# nrf5001 register map
Vendor: Nordic Semiconductor; Series: nRF50; File version: 1
CPU: CM0 r0p4, little endian, no MPU, no FPU, 2 interrupt priority bits, 32 interrupts
Registers are 32-bit, read-write, reset 0x0 unless marked. A register's access mark holds for its fields unless they carry their own. Offsets are from the block's base; [hi:lo] are bit positions; lines under a group give offsets from that group; {n}, {i} and the like mark numbered series; 'fields as' and 'values as' point back to an identical list; <NAME> marks a mode.

## RADIO (part 2 of 2) — 2.4 GHz radio
Base 0x40002000
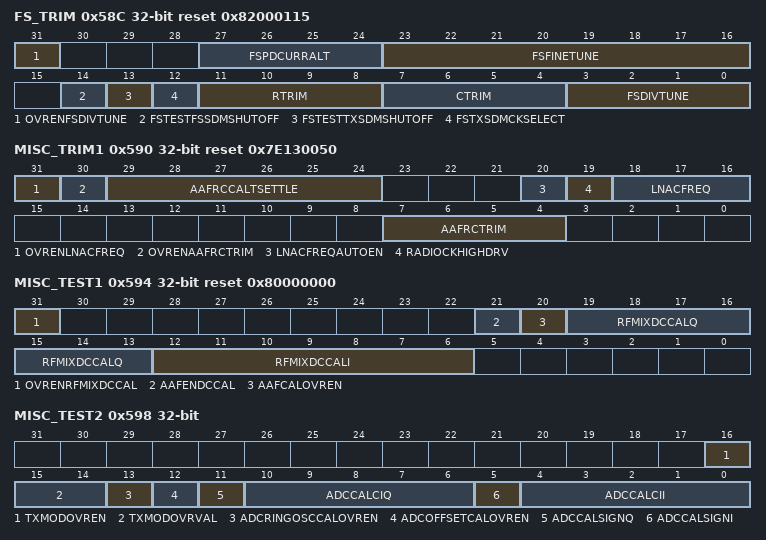
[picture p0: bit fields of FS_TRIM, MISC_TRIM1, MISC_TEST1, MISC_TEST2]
0x58C FS_TRIM reset 0x82000115 — Fs misc trim
  [31] OVRENFSDIVTUNE — if '1' enable override for FSDIVTUNE
  [27:24] FSPDCURRALT — Internal register to set FSPDCURR differently for some channels if FICR FSPDCURROPT is set to 1
  [23:16] FSFINETUNE — RF frequency adjustment (signed), LSB corresponds to 2 kHz, i.e. a range of +/-256 kHz
  [14] FSTESTFSSDMSHUTOFF — fsTestFsSdmShutoff. 1: Shutoff FsSDM, highest priority
  [13] FSTESTTXSDMSHUTOFF — fsTestTxSdmShutoff. 1: Shutoff TxSDM, e.g. for testing RX phase noise, highest priority
  [12] FSTXSDMCKSELECT — fsTxSdmCkSelect. 0: ck64MFs, 1: ck32M
  [11:8] RTRIM — Trim value for R in loop filter
  [7:4] CTRIM — Trim value for C in loop filter
  [3:0] FSDIVTUNE — Trim value for DIV2_4
0x590 MISC_TRIM1 reset 0x7E130050 — Misc Aaf/ADC trim related
  [31] OVRENLNACFREQ — if '1' enable override for LNACFREQ
  [30] OVRENAAFRCTRIM — if '1' enable override for AAFRCTRIM
  [29:24] AAFRCCALTSETTLE — Deprecated field - Sets number of clock pulses in the SETTLE state (calEngineTsettle)
  [20] LNACFREQAUTOEN — LNACFREQ automatically set based on selected channel
  [19] RADIOCKHIGHDRV — Enable high drive on RADIO_CK module
  [18:16] LNACFREQ — Change centre frequency of LNA LC tank
  [7:4] AAFRCTRIM — Process compensation for R and C
0x594 MISC_TEST1 reset 0x80000000 — Misc Aaf/ADC trim related
  [31] OVRENRFMIXDCCAL — if '1' enable override for RFMIXDCCALI/Q. RfMix calibration must only be run after the radio is fully powered up.
  [21] AAFENDCCAL — Enable DCCAL
  [20] AAFCALOVREN — 0: override with values in PAR1 1: use values from CalibrationEngineCore
  [19:13] RFMIXDCCALQ — AAF/RFMIX dc calibration of Q channel
  [12:6] RFMIXDCCALI — AAF/RFMIX dc calibration of I channel
0x598 MISC_TEST2 — Misc Aaf/ADC trim related
  [16] TXMODOVREN
  [15:14] TXMODOVRVAL
  [13] ADCRINGOSCCALOVREN — 1: override with values in SPI 0: use values from CalibrationEngineCore
  [12] ADCOFFSETCALOVREN — 1: override with values in SPI 0: use values from CalibrationEngineCore
  [11] ADCCALSIGNQ — ADC cal sign for Q
  [10:6] ADCCALCIQ — ADC calibration current in 'Q' comparator.
  [5] ADCCALSIGNI — ADC cal sign for I
  [4:0] ADCCALCII — ADC calibration current in 'I' comparator.
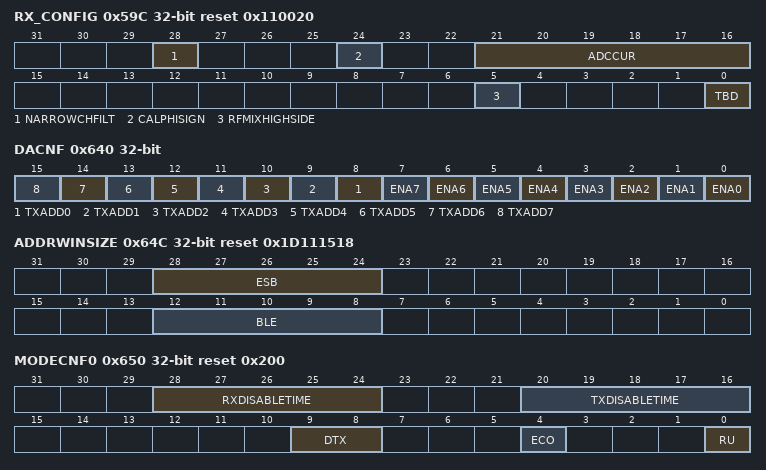
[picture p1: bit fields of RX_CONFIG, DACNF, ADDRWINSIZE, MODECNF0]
0x59C RX_CONFIG reset 0x110020 — Misc RX config
  [28] NARROWCHFILT — if '1', the channel filter is slightly narrowed
  [24] CALPHISIGN — If '1', then the sign of the phase correction value in RxIQMix is inverted
  [21:16] ADCCUR
  [5] RFMIXHIGHSIDE — Swap MIX_In and MIX_IP outputs if high (enables use of 'high side' mixing)
  [0] TBD — Deprecated field - Set to '1' if high-side LO
{0x600+4i} DAB[{i}] (i=0..7) — Description collection: Device address base segment n
  [31:0] DAB — Device address base segment n
{0x620+4i} DAP[{i}] (i=0..7) — Description collection: Device address prefix n
  [15:0] DAP — Device address prefix n
0x640 DACNF — Device address match configuration
  [n+8] TXADD{n} (n=0..7) — TxAdd for device address {n}
  [n] ENA{n} (n=0..7) — Enable or disable device address matching using device address {n}
    0=Disabled; 1=Enabled
0x64C ADDRWINSIZE reset 0x1D111518 — address match safe window size (the number of bits after detect is asserted, before starting to look for address match). Only valid when OVERRIDE22.DISABLEADDRWINDOW is '0'
  [28:24] ESB — Number of bits after detect to start search address/SFD in ESB mode
  [12:8] BLE — Number of bits after detect to start search address/SFD in BLE mode
0x650 MODECNF0 reset 0x200 — Radio mode configuration register 0
  [28:24] RXDISABLETIME — Transition time from RXDISABLE state to DISABLED state
  [20:16] TXDISABLETIME — Transition time from TXDISABLE state to DISABLED state
  [9:8] DTX — Default TX value
    0=B1 (Transmit '1'); 1=B0 (Transmit '0'); 2=Center (Transmit center frequency)
  [4] ECO — Energy mode
    0=Default energy mode; 1=Eco (Eco (energy) mode)
  [0] RU — Radio ramp-up time
    0=Default ramp-up time (tRXEN and tTXEN), compatible with firmware written for nRF51; 1=Fast ramp-up (tRXEN,FAST and tTXEN,FAST), see electrical specification for more information
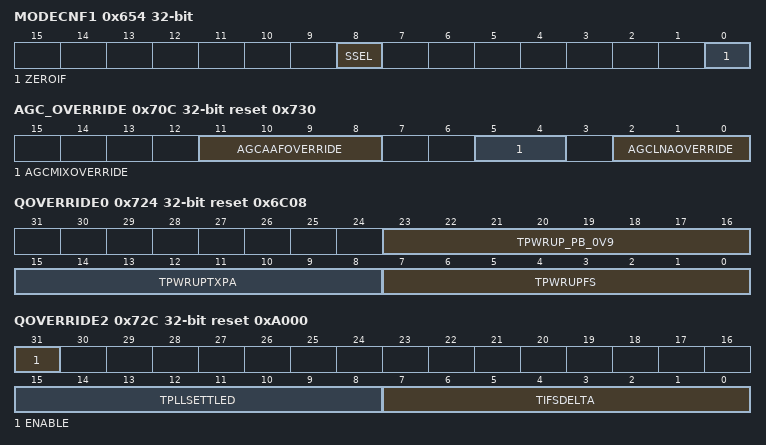
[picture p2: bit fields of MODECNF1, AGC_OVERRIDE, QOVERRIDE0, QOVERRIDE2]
0x654 MODECNF1 — Radio mode configuration register 1
  [8] SSEL — Sideband select
    0=Low (Low-side LO); 1=High-side LO
  [0] ZEROIF
    0=Default mode (heterodyne); 1=Zero-IF mode
0x704 AGC_TOGGLE — Constant AGC Gain switching, Debug
  [1:0] AGC_TOGGLE — Enable or disable functional testmode for AGC
    0=Disabled; 1=Enabled
0x708 AGC_EN reset 0x1 — AGC enable
  [0] AGC_EN — Enable or disable AGC
    0=Disabled; 1=Enabled
0x70C AGC_OVERRIDE reset 0x730 — Gain setting
  [11:8] AGCAAFOVERRIDE — Override for Aaf gain
  [5:4] AGCMIXOVERRIDE — Override for Mix gain
  [2:0] AGCLNAOVERRIDE — Override for Lna gain
0x724 QOVERRIDE0 reset 0x6C08 — Trim value override register 0 for nRF52
  [23:16] TPWRUP_PB_0V9 — Override for tPWRUP_PB_0V9
  [15:8] TPWRUPTXPA — Override for tPwrupTxPa
  [7:0] TPWRUPFS — Override for tPwrupFs
0x728 QOVERRIDE1 reset 0x680000 — Trim value override register 1 for nRF52
  [23:16] TPWRUPTX — Override for tPwrupTx
0x72C QOVERRIDE2 reset 0xA000 — Trim value override register 2 for nRF52
  [31] ENABLE — if '1' enable override for TIFSDELTA
  [15:8] TPLLSETTLED — Override for tPllSettled
  [7:0] TIFSDELTA — Override for tIfsDelta
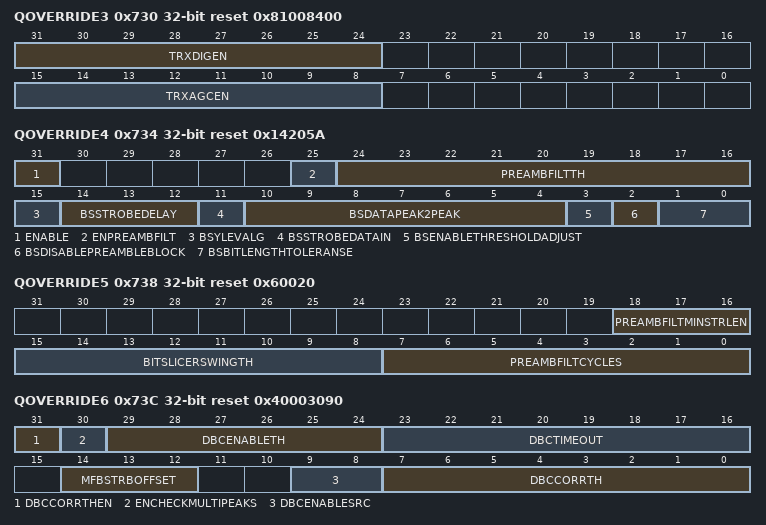
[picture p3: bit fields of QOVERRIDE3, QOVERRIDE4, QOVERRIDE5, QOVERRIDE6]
0x730 QOVERRIDE3 reset 0x81008400 — Trim value override register 3 for nRF52
  [31:24] TRXDIGEN — Override for tRxDigEn
  [15:8] TRXAGCEN — Override for tRxAgcEn
0x734 QOVERRIDE4 reset 0x14205A — Trim value override register 4 for nRF52
  [31] ENABLE — Enable or disable override of default trim values
    0=Disabled; 1=Enabled
  [25] ENPREAMBFILT — Enable preamble filter
  [24:16] PREAMBFILTTH — Threshold for the preamble filter
  [15] BSYLEVALG — Override for bsYlevAlg
  [14:12] BSSTROBEDELAY — Override for bsStrobeDelay
  [11] BSSTROBEDATAIN — Override for bsStrobeDataIn
  [10:4] BSDATAPEAK2PEAK — Override for bsDataPeak2Peak
  [3] BSENABLETHRESHOLDADJUST — Override for bsEnableThresholdAdjust
  [2] BSDISABLEPREAMBLEBLOCK — Override for bsDisablePreambleBlock
  [1:0] BSBITLENGTHTOLERANSE — Override for bsBitLengthToleranse
0x738 QOVERRIDE5 reset 0x60020 — Trim value override register 5 for nRF52
  [18:16] PREAMBFILTMINSTRLEN — Override value for preambFiltMinStrLen
  [15:8] BITSLICERSWINGTH — Override value for bitSlicerSwingTh
  [7:0] PREAMBFILTCYCLES — Override value for preambFiltCycles
0x73C QOVERRIDE6 reset 0x40003090 — Trim value override register 6 for nRF52
  [31] DBCCORRTHEN — Override value enable for DBCCORRTH and MFBSTRBOFFSET
  [30] ENCHECKMULTIPEAKS — Enable checking of several correlator peaks in hypermode
  [29:24] DBCENABLETH — Override value for correlator enable threshold
  [23:16] DBCTIMEOUT — Override value for correlator timeout,in bit periods (hypermode)
  [14:12] MFBSTRBOFFSET — Override value for strobe offset
  [9:8] DBCENABLESRC — Override value for dbcEnableSrc
    0=Always on when not address match; 1=BBLogMag (When bbLogMag is above a threshold); 2=BitSlicerSwing (When a certain time has gone since the input to the bitslicer was above BITSLICERSWINGTH); 3=Both BBLogMag and BitSlicerSwing
  [7:0] DBCCORRTH — Override value for correlation Threshold
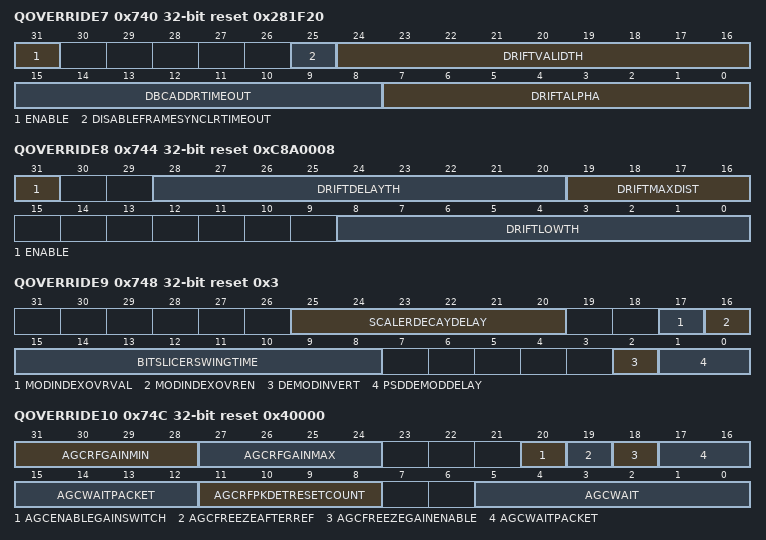
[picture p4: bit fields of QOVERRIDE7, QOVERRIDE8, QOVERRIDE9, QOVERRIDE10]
0x740 QOVERRIDE7 reset 0x281F20 — Trim value override register 7 for nRF52
  [31] ENABLE — Override enable for DRIFTALPHA, DBCADDRTIMEOUT and DRIFTVALIDTH
  [25] DISABLEFRAMESYNCLRTIMEOUT — Disable framesync timeout (early address match timeout) for BLE LR mode. No override-enable to set for this (hypermode)
  [24:16] DRIFTVALIDTH — Override value for driftValidTh, drift estimator (hypermode)
  [15:8] DBCADDRTIMEOUT — Override value for address match timeout, [in bit periods] (hypermode)
  [7:0] DRIFTALPHA — Override value for IIR feedback , drift estimator (hypermode)
0x744 QOVERRIDE8 reset 0xC8A0008 — Trim value override register 8 for nRF52
  [31] ENABLE — Override value enable for override register 8
  [28:20] DRIFTDELAYTH — Override value for driftDelayTh, drift estimator (hypermode)
  [19:16] DRIFTMAXDIST — Override value for driftMaxDist, drift estimator (hypermode)
  [8:0] DRIFTLOWTH — Override value for driftLowTh, drift estimator (hypermode)
0x748 QOVERRIDE9 reset 0x3 — Trim value override register 9 for nRF52
  [25:20] SCALERDECAYDELAY — Decay delay for the IQ scaler
  [17] MODINDEXOVRVAL
  [16] MODINDEXOVREN
  [15:8] BITSLICERSWINGTIME
  [2] DEMODINVERT — Override value for demodInvert (standard and hyper)
  [1:0] PSDDEMODDELAY — Override value for psdDemodDelay (standard mode)
0x74C QOVERRIDE10 reset 0x40000 — Trim value override register 10 for nRF52
  [31:28] AGCRFGAINMIN — Override value for agcRFGainMin
  [27:24] AGCRFGAINMAX — Override value for agcRFGainMax
  [20] AGCENABLEGAINSWITCH — Override value for agcEnableGainSwitch
  [19] AGCFREEZEAFTERREF — Modifier bit for AGCFREEZEGAINENABLE
    0=EntireCTE (Gain freeze will apply to whole CTE); 1=AfterRefPeriod (Gain freeze will apply only after the reference period of the CTE)
  [18] AGCFREEZEGAINENABLE — Override AGC gain setting during CTE
    0=Adjust (AGC gain settings will keep adjusting during CTE); 1=Freeze (AGC gain settings will freeze (not keep adjusting) during CTE)
  [17:12] AGCWAITPACKET — Override value for agcWaitPacket
  [11:8] AGCRFPKDETRESETCOUNT — Override value for agcRFpkDetResetCount
  [5:0] AGCWAIT — Override value for agcWait
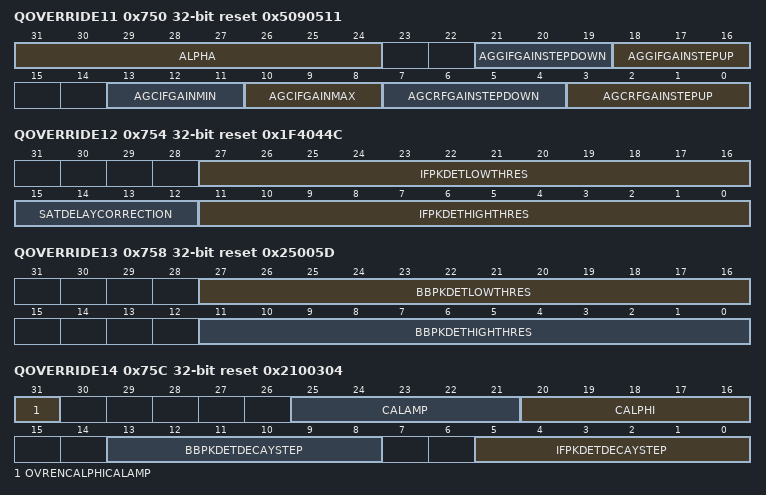
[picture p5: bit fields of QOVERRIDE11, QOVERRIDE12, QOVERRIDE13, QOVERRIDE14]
0x750 QOVERRIDE11 reset 0x5090511 — Trim value override register 11 for nRF52
  [31:24] ALPHA — used in Rssi moving exponential averager
  [21:19] AGGIFGAINSTEPDOWN — Override value for aggIFgainStepDown
  [18:16] AGGIFGAINSTEPUP — Override value for aggIFgainStepUp
  [13:11] AGCIFGAINMIN — Override value for agcIFgainMin
  [10:8] AGCIFGAINMAX — Override value for agcIFgainMax
  [7:4] AGCRFGAINSTEPDOWN — Override value for agcRFgainStepDown
  [3:0] AGCRFGAINSTEPUP — Override value for agcRFgainStepUp
0x754 QOVERRIDE12 reset 0x1F4044C — Trim value override register 12 for nRF52
  [27:16] IFPKDETLOWTHRES — Override value for IfpkDetLowThres
  [15:12] SATDELAYCORRECTION — Signed correction value for how much the saturation information is delayed from the input ADC samples to the samples being stored to RAM in direction finding operation
  [11:0] IFPKDETHIGHTHRES — Override value for IfpkDetHighThres
0x758 QOVERRIDE13 reset 0x25005D — Trim value override register 13 for nRF52
  [27:16] BBPKDETLOWTHRES — Override value for BbpkDetLowThres
  [11:0] BBPKDETHIGHTHRES — Override value for BbpkDetHighThres
0x75C QOVERRIDE14 reset 0x2100304 — Trim value override register 14 for nRF52
  [31] OVRENCALPHICALAMP — if '1' enable override for CALPHI/CALAMP
  [25:21] CALAMP — Override value for calamp (programmable IandQ gain mismatch correction)
  [20:16] CALPHI — Override value for calphi (programmable IandQ phase mismatch correction)
  [13:8] BBPKDETDECAYSTEP — Override value for BbpkDetDecayStep
  [5:0] IFPKDETDECAYSTEP — Override value for IfpkDetDecayStep
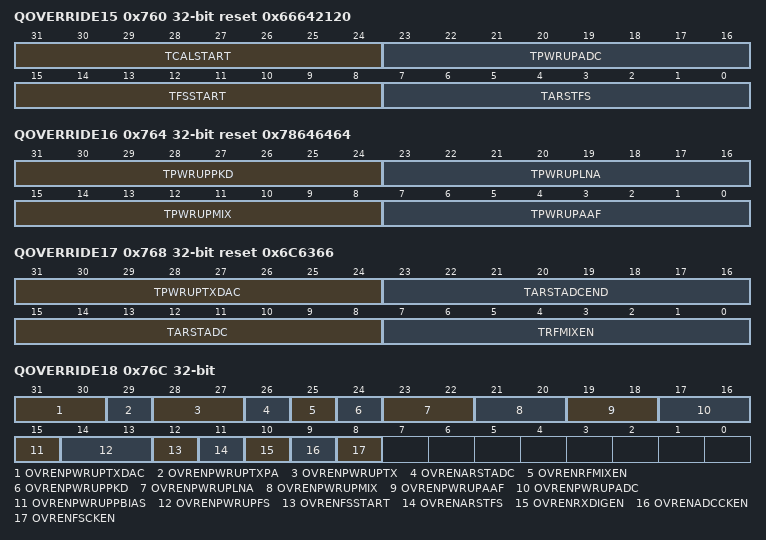
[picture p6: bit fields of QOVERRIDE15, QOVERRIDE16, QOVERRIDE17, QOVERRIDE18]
0x760 QOVERRIDE15 reset 0x66642120 — Trim value override register 15 for nRF52
  [31:24] TCALSTART — Override value for tCalStart
  [23:16] TPWRUPADC — Override value for tPwrupAdc
  [15:8] TFSSTART — Override value for tFsStart
  [7:0] TARSTFS — Override value for tArstFs
0x764 QOVERRIDE16 reset 0x78646464 — Trim value override register 16 for nRF52
  [31:24] TPWRUPPKD — Override value for tPwrupPkd
  [23:16] TPWRUPLNA — Override value for tPwrupLna
  [15:8] TPWRUPMIX — Override value for tPwrupMix
  [7:0] TPWRUPAAF — Override value for tPwrupAaf
0x768 QOVERRIDE17 reset 0x6C6366 — Trim value override register 17 for nRF52
  [31:24] TPWRUPTXDAC — Override value for tPwrupTxDac
  [23:16] TARSTADCEND — Override value for tArstAdcEnd
  [15:8] TARSTADC — Override value for tArstAdc
  [7:0] TRFMIXEN — Override value for tRfMixEn
0x76C QOVERRIDE18 — Trim value override register 18 for nRF52
  [31:30] OVRENPWRUPTXDAC — Override enable: ovrEnPwrupTxDac
  [29] OVRENPWRUPTXPA — Override enable: ovrEnPwrupTxPa
  [28:27] OVRENPWRUPTX — Override enable: ovrEnPwrupTx
  [26] OVRENARSTADC — Override enable: ovrEnArstAdc
  [25] OVRENRFMIXEN — Override enable: ovrEnRfMixEn
  [24] OVRENPWRUPPKD — Override enable: ovrEnPwrupPkd
  [23:22] OVRENPWRUPLNA — Override enable: ovrEnPwrupLna
  [21:20] OVRENPWRUPMIX — Override enable: ovrEnPwrupMix
  [19:18] OVRENPWRUPAAF — Override enable: ovrEnPwrupAaf
  [17:16] OVRENPWRUPADC — Override enable: ovrEnPwrupAdc
  [15] OVRENPWRUPPBIAS — Override enable: ovrEnPwrupPbias
  [14:13] OVRENPWRUPFS — Override enable: ovrEnPwrupFs
  [12] OVRENFSSTART — Override enable: ovrEnFsStart
  [11] OVRENARSTFS — Override enable: ovrEnArstFs
  [10] OVRENRXDIGEN — Override enable: ovrEnRxDigEn
  [9] OVRENADCCKEN — Override enable: ovrEnAdcCkEn
  [8] OVRENFSCKEN — Override enable: ovrEnFsCkEn
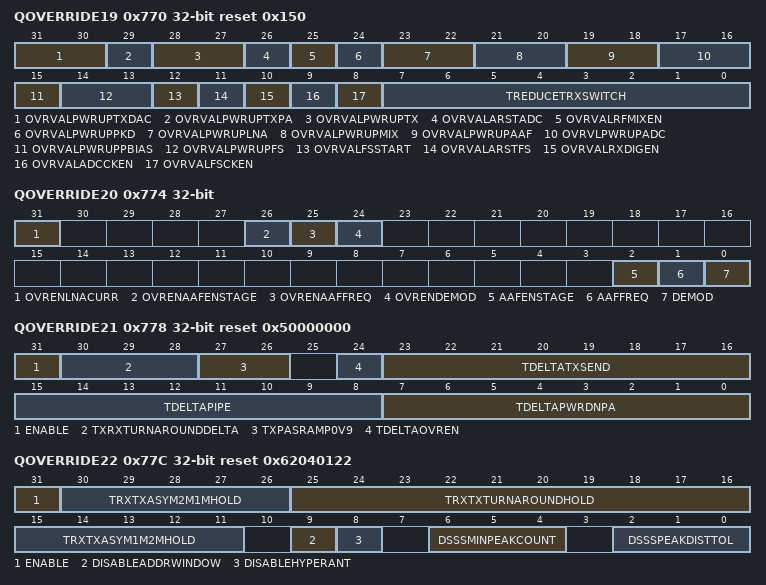
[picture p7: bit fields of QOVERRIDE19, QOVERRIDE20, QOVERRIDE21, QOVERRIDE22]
0x770 QOVERRIDE19 reset 0x150 — Trim value override register 19 for nRF52
  [31:30] OVRVALPWRUPTXDAC — Override value: ovrValPwrupTxDac
  [29] OVRVALPWRUPTXPA — Override value: ovrValPwrupTxPa
  [28:27] OVRVALPWRUPTX — Override value: ovrValPwrupTx
  [26] OVRVALARSTADC — Override value: ovrValArstAdc
  [25] OVRVALRFMIXEN — Override value: ovrValRfMixEn
  [24] OVRVALPWRUPPKD — Override value: ovrValPwrupPkd
  [23:22] OVRVALPWRUPLNA — Override value: ovrValPwrupLna
  [21:20] OVRVALPWRUPMIX — Override value: ovrValPwrupMix
  [19:18] OVRVALPWRUPAAF — Override value: ovrValPwrupAaf
  [17:16] OVRVLPWRUPADC — Override value: ovrVlPwrupAdc
  [15] OVRVALPWRUPPBIAS — Override value: ovrValPwrupPbias
  [14:13] OVRVALPWRUPFS — Override value: ovrValPwrupFs
  [12] OVRVALFSSTART — Override value: ovrValFsStart
  [11] OVRVALARSTFS — Override value: ovrValArstFs
  [10] OVRVALRXDIGEN — Override value: ovrValRxDigEn
  [9] OVRVALADCCKEN — Override value: ovrValAdcCkEn
  [8] OVRVALFSCKEN — Override value: ovrValFsCkEn
  [7:0] TREDUCETRXSWITCH — Override value: tReduceTrxSwitch
0x774 QOVERRIDE20 — Trim value override register 20 for nRF52
  [31] OVRENLNACURR — if '1' enable override for LNACURR
  [26] OVRENAAFENSTAGE — if '1' enable override for AAFENSTAGE
  [25] OVRENAAFFREQ — if '1' enable override for AAFFREQ
  [24] OVRENDEMOD — if '1' enable override for DEMOD
  [2] AAFENSTAGE — Enable extra AAF filter stage
  [1] AAFFREQ — IF frequency, 0=1MHz (for < =1Mbps), 1=2MHz (for 2Mbps)
  [0] DEMOD — Demodulator mode override value. 1=hyper,0=standard
    0=Standard (Hypermode disabled (override value)); 1=Hypermode enabled (override value)
0x778 QOVERRIDE21 reset 0x50000000 — Trim value override register 21 for nRF52
  [31] ENABLE — Enable or disable override of default trim values
    0=Disabled; 1=Enabled
  [30:28] TXRXTURNAROUNDDELTA — Tuning of radio turn around timing
  [27:26] TXPASRAMP0V9 — Debug: Control of PA RAMP time, Up/ down
  [24] TDELTAOVREN — Override enable
  [23:16] TDELTATXSEND — Override for tDeltaTxSend (full resolution)
  [15:8] TDELTAPIPE — Override for tDeltaPipe (full resolution)
  [7:0] TDELTAPWRDNPA — Override for tDeltaPwrdnPa (full resolution)
0x77C QOVERRIDE22 reset 0x62040122 — Trim value override register 22 for nRF52
  [31] ENABLE — Enable or disable override for DSSSPEAKDISTTOL and DSSSMINPEAKCOUNT
    0=Disabled; 1=Enabled
  [30:26] TRXTXASYM2M1MHOLD — TIFS positive offset when the mode is switched from 2M to 1M
  [25:16] TRXTXTURNAROUNDHOLD — Additional delay to hold Tx/Rx turnaround, full resolution [250ns]
  [15:11] TRXTXASYM1M2MHOLD — TIFS negative offset when the mode is switched from 1M to 2M
  [9] DISABLEADDRWINDOW — Disable or enable the qualification of addressMatch vs. detect
    1=Disabled; 0=Enabled
  [8] DISABLEHYPERANT — Disable or enable hypermode fix for ANT
    1=Disabled; 0=Enabled
  [6:4] DSSSMINPEAKCOUNT — Override for dsssMinPeakCount
  [2:0] DSSSPEAKDISTTOL — Override for dsssPeakDistanceTolerance
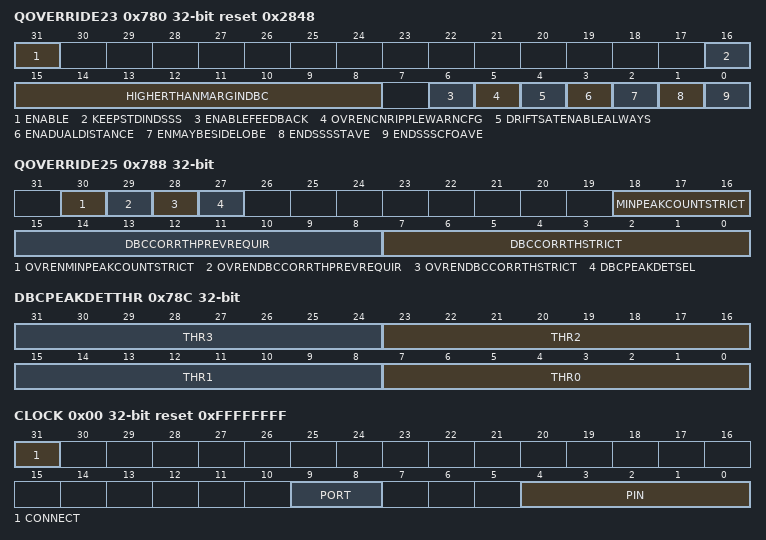
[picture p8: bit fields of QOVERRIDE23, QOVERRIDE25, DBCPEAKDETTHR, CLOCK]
0x780 QOVERRIDE23 reset 0x2848 — Trim value override register 23 for nRF52
  [31] ENABLE — Enable override for OVERRIDE23 (except HIGHERTHANMARGINDBC and OVRENCNRIPPLEWARNCFG)
  [16] KEEPSTDINDSSS — Keep standard demod in DSSS mode
  [15:8] HIGHERTHANMARGINDBC — Required peak height required for a double correlator peak to be considered higher than previous ones. The register value will be multiplied by 25 to obtain the actual margin. The bitfield is NOT subject to the enable override at bit position 31, and will always be enabled for hypermode.
  [6] ENABLEFEEDBACK — Enable decision feedback for matched filter bank
  [5] OVRENCNRIPPLEWARNCFG — Override enable for CNPEAKMINTHR and CNABSMAXTHR in the CNRIPPLEWARNCFG register
  [4] DRIFTSATENABLEALWAYS — Enable saturation in drift calculator for all modes
  [3] ENADUALDISTANCE — Allow dual distance between peaks
  [2] ENMAYBESIDELOBE — Ignore peaks from DBC which look like sidelobes
  [1] ENDSSSSTAVE — Enable strobe time averaging
  [0] ENDSSSCFOAVE — Enable CFO averaging
0x788 QOVERRIDE25 — Unspecified
  [30] OVRENMINPEAKCOUNTSTRICT — Override enable for MINPEAKCOUNTSTRICT
  [29] OVRENDBCCORRTHPREVREQUIR — Override enable for DBCCORRTHPREVREQUIR
  [28] OVRENDBCCORRTHSTRICT — Override enable for DBCCORRTHSTRICT
  [27] DBCPEAKDETSEL — DBC peak detector selection
    0=Classic (Use classic peak detector (backward compatible behavior)); 1=Differential (Use differential peak detector)
  [18:16] MINPEAKCOUNTSTRICT — Min number of peaks to detect before resyncing to another preamble while already working on a previous preamble in BleLrx.
  [15:8] DBCCORRTHPREVREQUIR — Correlation threshold for double correlator used in BleLr mode to reject a later resync using DBCCORRTHSTRICT.
  [7:0] DBCCORRTHSTRICT — Correlation threshold for double correlator used in BleLr mode to resync to another preamble while already working on a previous preamble.
0x78C DBCPEAKDETTHR — Thresholds for each peak detector instance
  [8n+7:8n] THR{n} (n=0..3) — Diff threshold {n}
0x800 DEBUGPSEL group — Unspecified
  0x00 CLOCK reset 0xFFFFFFFF — Pin select for RADIO clock (direct mode, base band debug. Refer to digip_064 and digip_061, txCk and ckDataIn signals)
    [31] CONNECT — Connection
      1=Disconnected; 0=Connected
    [9:8] PORT — Port number
    [4:0] PIN — Pin number
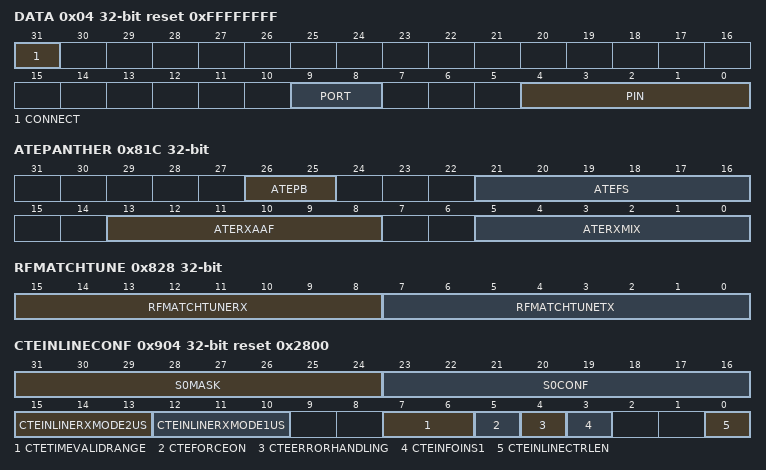
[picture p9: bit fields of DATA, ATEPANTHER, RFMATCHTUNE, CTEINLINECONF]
  0x04 DATA reset 0xFFFFFFFF — Pin select for RADIO data (direct mode, base band debug. Refer to digip_064 and digip_061, txRadioData and dataIn signals)
    fields as DEBUGPSEL.CLOCK
0x81C ATEPANTHER — Analog test bus control for Panther radio
  [26:25] ATEPB
  [21:16] ATEFS — ateFs: Configuration register for automatic test bus
  [13:8] ATERXAAF — ateRxAaf: Enable RXAAF test mode when >0
  [5:0] ATERXMIX — ateRxMix: Enable RXMix test mode when >0
0x828 RFMATCHTUNE — Adjust transformation ratio of on-chip matching Can be used for: 1) Optimise power consumption for different output power levels in TX mode 2) Optimise input impedance in RX mode.
  [15:8] RFMATCHTUNERX — Antenna match tuning for RX mode
  [7:0] RFMATCHTUNETX — Antenna match tuning for TX mode
0x900 DFEMODE — Whether to use Angle-of-Arrival (AOA) or Angle-of-Departure (AOD)
  [1:0] DFEOPMODE — Direction finding operation mode
    0=Disabled (Direction finding mode disabled); 2=AoD (Direction finding mode set to AoD); 3=AoA (Direction finding mode set to AoA)
0x904 CTEINLINECONF reset 0x2800 — Configuration for CTE inline mode
  [31:24] S0MASK — S0 bit mask to set which bit to match
  [23:16] S0CONF — S0 bit pattern to match
  [15:13] CTEINLINERXMODE2US — Spacing between samples for the samples in the SWITCHING period when CTEINLINEMODE is set
    0=8us; 1=4us; 2=2us; 3=1us; 4=500ns (0.5us); 5=250ns (0.25us); 6=125ns (0.125us)
  [12:10] CTEINLINERXMODE1US — Spacing between samples for the samples in the SWITCHING period when CTEINLINEMODE is set
    values as CTEINLINERXMODE2US
  [7:6] CTETIMEVALIDRANGE — Max range of CTETime
    0=20 in 8us unit (default) Set to 20 if parsed CTETime is larger han 20; 1=31 in 8us unit; 2=63 in 8us unit
  [5] CTEFORCEON — CTE is continuously output after CRC and only stopped by triggering TASKS_STOP. This is typically used together with the DFEEND to STOP short. AoA/AoD procedure duration is still controlled by DFECTRL1.NUMBEROF8S / CTETIME
    1=Yes (CTE is continuously transmitted after CRC until TASKS_STOP); 0=No (CTE duration is automatically determined by DFECTRL1.NUMBEROF8US / CTETIME (only correct for 1Mbps and 2Mbps modes))
  [4] CTEERRORHANDLING — Sampling/switching if CRC is not OK
    1=Yes (Sampling and antenna switching also when CRC is not OK); 0=No (No sampling and antenna switching when CRC is not OK)
  [3] CTEINFOINS1 — CTEInfo is S1 byte or not
    1=InS1 (CTEInfo is in S1 byte (data PDU)); 0=NotInS1 (CTEInfo is NOT in S1 byte (advertising PDU))
  [0] CTEINLINECTRLEN — Enable parsing of CTEInfo from received packet in BLE modes
    1=Enabled (Parsing of CTEInfo is enabled); 0=Disabled (Parsing of CTEInfo is disabled)
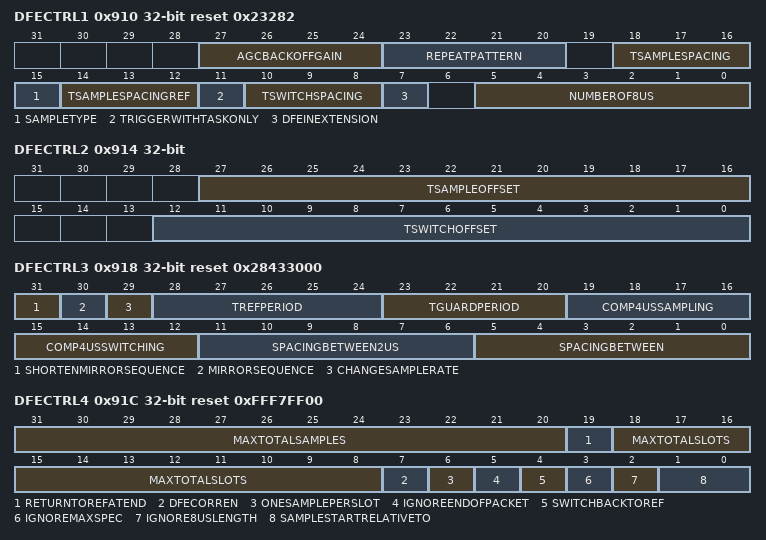
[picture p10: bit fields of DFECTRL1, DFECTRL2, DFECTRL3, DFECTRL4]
0x910 DFECTRL1 reset 0x23282 — Various configuration for Direction finding
  [27:24] AGCBACKOFFGAIN — Gain will be lowered by the specified number of gain steps at the start of CTE
  [23:20] REPEATPATTERN — Repeat each individual antenna pattern N times sequentially, i.e. P0, P0, P1, P1, P2, P2, P3, P3, etc.
    0=NoRepeat (Do not repeat (1 time in total))
  [18:16] TSAMPLESPACING — Interval between samples in the SWITCHING period when CTEINLINECTRLEN is 0
    1=4us; 2=2us; 3=1us; 4=500ns (0.5us); 5=250ns (0.25us); 6=125ns (0.125us)
  [15] SAMPLETYPE — Whether to sample I/Q or magnitude/phase
    0=IQ (Complex samples in I and Q); 1=MagPhase (Complex samples as magnitude and phase)
  [14:12] TSAMPLESPACINGREF — Interval between samples in the REFERENCE period
    values as CTEINLINECONF.CTEINLINERXMODE2US
  [11] TRIGGERWITHTASKONLY — Trigger AoA/AoD procedure using only task
    1=OnlyTask (Only allow triggering a procedure with TASKS_DFESTART); 0=Multiple (Trigger also with other signals)
  [10:8] TSWITCHSPACING — Interval between every time the antenna is changed in the SWITCHING state
    0=8us; 1=4us; 2=2us; 3=1us; 4=500ns (0.5us); 5=250ns (0.25us)
  [7] DFEINEXTENSION — Add CTE extension and do antenna switching/sampling in this extension
    1=CRC (AoA/AoD procedure triggered at end of CRC); 0=Payload (Antenna switching/sampling is done in the packet payload)
  [5:0] NUMBEROF8US — Length of the AoA/AoD procedure in number of 8 us units
0x914 DFECTRL2 — Start offset for Direction finding
  [27:16] TSAMPLEOFFSET — Signed value offset before starting sampling in number of 16M cycles relative to the beginning of the REFERENCE state - 12 us after switching start
  [12:0] TSWITCHOFFSET — Signed value offset after the end of the CRC before starting switching in number of 16M cycles
0x918 DFECTRL3 reset 0x28433000 — Various hacker/tuning configuration for Direction finding
  [31] SHORTENMIRRORSEQUENCE — Applies only when MIRRORSEQUENCE is set. Selects whether to repeat the end pattern (in both ends) or not
    0=Disable (End patterns are repeated); 1=Enable (End patterns are not repeated)
  [30] MIRRORSEQUENCE — When reaching the last antenna pattern, it repeats that pattern, and then goes back down again.
    0=Disable (Do not mirror the sequence); 1=Enable (Mirror the sequence)
  [29] CHANGESAMPLERATE — Whether to have the ability to have separate sampling rate in the REFERENCE period vs the SWITCHING state
    0=Same (Always use sample spacing given by TSAMPLESPACINGREF); 1=Change (Use TSAMPLESPACINGREF in the REFERENCE period, and TSAMPLESPACING or CTEINLINEAODRXMODExUS in the SWITCHING period)
  [28:24] TREFPERIOD — Length of REFERENCE period in number of microseconds, normally 8
  [23:20] TGUARDPERIOD — Length of GUARD period in number of microseconds, normally 4
  [19:16] COMP4USSAMPLING — Number of 4us periods to subtract from numberOf8us when calculating total number of samples to capture
  [15:12] COMP4USSWITCHING — Number of 4us periods to subtract from numberOf8us when calculating total number of antenna slots switches
  [11:6] SPACINGBETWEEN2US — Same as SPACINGBETWEEN when using CTEINLINECTRL and CTEType is 2 us slots
  [5:0] SPACINGBETWEEN — Signed tuning value for the spacing between the last sample in the reference period and the first sample in the first sample slot
0x91C DFECTRL4 reset 0xFFF7FF00 — Various hacker/tuning configuration for Direction finding
  [31:20] MAXTOTALSAMPLES — Maximum number of samples to capture
  [19] RETURNTOREFATEND — Start position of repeated part of switching pattern sequence
    0=Disable (Return to SWITCHPATTERN[2] after reaching the end of the switching pattern sequence); 1=Enable (Return to SWITCHPATTERN[1] after reaching the end of the switching pattern sequence)
  [18:8] MAXTOTALSLOTS — Maximum number of antenna slots
  [7] DFECORREN — Enable correlator before Direction Finding samples
    0=Disable correlator; 1=Enable correlator
  [6] ONESAMPLEPERSLOT — TSAMPLESPACING is ignored for the samples taken in the SWITCHING state TSAMPLESPACINGREF is still used for the first samples (REFERENCE period)
  [5] IGNOREENDOFPACKET — Ignore that the UTxRxChain says that the packet has been received Continue running if more time to run
    0=Do not ignore the end of packet; 1=Ignore the end of packet
  [4] SWITCHBACKTOREF — Insert reference antenna(SWITCHPATTERN[1]) between antenna switches, from SWITCHPATTERN[2] onwards
    0=Disable (Do not insert reference antenna between switches); 1=Enable (Insert reference antenna between switches)
  [3] IGNOREMAXSPEC — Ignore the maximum number of samples and antenna slots specified with MAXTOTALSAMPLES and MAXTOTALSLOTS
    0=DoNotIgnore (Use the max specs); 1=Ignore the max specs
  [2] IGNORE8USLENGTH — Ignore the length specification in numberOf8us
    0=DoNotIgnore (Use the length specification); 1=Ignore the length specification
  [1:0] SAMPLESTARTRELATIVETO — Start point of TSAMPLEOFFSET sampling relative to which part in the switching state machine
    0=Reference (At the start of the reference antenna period); 1=Switching (At the start of antenna switching after the reference antenna period); 2=Trigger (When it is triggered Either TASKS_DFESTART, address match or AoA/AoD procedure trigger source); 3=Guard (At the start of the GUARD period)
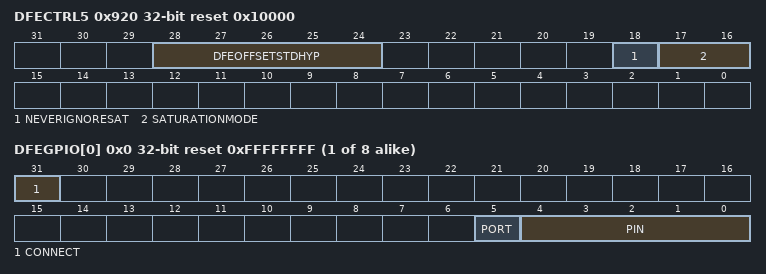
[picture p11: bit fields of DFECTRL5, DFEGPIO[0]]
0x920 DFECTRL5 reset 0x10000 — Various hacker/tuning configuration for Direction finding
  [28:24] DFEOFFSETSTDHYP — Tuning of the timing difference between the hypermode demodulator and the standard demodulator for the DFE start event, in 62.5 ns units
  [18] NEVERIGNORESAT — Selects whether saturation (being reported from the radio front-end) should be ignored in the beginning of the slot or not
    0=Ignore (Saturation being indicated from the front-end is ignored if it happens in the first 40 percent of the sample spacing after a sample was saved to RAM); 1=NeverIgnore (Saturation is always reported in RAM if detected by the frontend)
  [17:16] SATURATIONMODE — Set how input saturation will be present in the captured samples
    0=No saturation is presented; 1=MinVal (Saturation is marked by setting both I and Q to -32768 (or mag/phase if SAMPLETYPE is 1)); 2=SaturationBit (Bit 15 of both the I and Q values indicates saturation. I and Q are hence only 15 bit values)
0x928 SWITCHPATTERN — GPIO patterns to be used for each antenna
  [7:0] SWITCHPATTERN — Fill array of GPIO patterns for antenna control
0x92C CLEARPATTERN — Clear the GPIO pattern array for antenna control
  [0] CLEARPATTERN write-1-clears — Clears GPIO pattern array for antenna control
    1=Clear the GPIO pattern
0x930 PSEL group — Unspecified
  {0x0+4j} DFEGPIO[{j}] (j=0..7) reset 0xFFFFFFFF — Description collection: Pin select for DFE pin n
    [31] CONNECT — Connection
      1=Disconnected; 0=Connected
    [5] PORT — Port number
    [4:0] PIN — Pin number
0x950 DFEPACKET group — DFE packet EasyDMA channel
  0x00 PTR reset 0x1000000 — Data pointer
  0x04 MAXCNT reset 0x1000 — Maximum number of buffer words to transfer
    [13:0] MAXCNT
  0x08 AMOUNT ro — Number of samples transferred in the last transaction
    [15:0] AMOUNT
0x960 DFEDMAEND — END event for DFE DMA without PPI nor IRQ
  [0] DFEDMAEND — END event for DFE DMA
0x964 DFEDMASTART — Manually start DmaChannelPeripheral for DFE
  [0] DFEDMASTART
0x968 DFEDMASTOP — Force stop DmaChannelPeripheral for DFE
  [0] DFEDMASTOP
0xA30 ACQENABLE — Enable or disable data acquisition (refer to 4378_164)
  [0] ENABLE — Enable or disable data acquisition
    0=Disabled (Data acquisition is disabled); 1=Enabled (Data acquisition is enabled)
0xA34 ACQDMA group — EasyDMA channel for data acquisition (refer to 4378_164)
  0x00 PTR reset 0x1000000 — EasyDMA pointer for data acquisition (refer to 4378_164)
    [31:0] PTR — EasyDMA pointer for data acquisition
  0x04 MAXCNT — Maximum number of 32-bit words to transfer (refer to 4378_164)
    [15:0] MAXCNT — Maximum number of 32-bit words to transfer
  0x08 AMOUNT ro — Number of 32-bit words transferred in the last transaction (refer to 4378_164)
    [15:0] AMOUNT — Number of 32-bit words transferred in the last transaction
0xA40 ACQMODE — Data acquisition capture mode (refer to 4378_164)
  [1:0] ACQMODE — Data acquisition capture mode
    0=IANDQ (Logging ADCI and ADCQ); 1=IQANDFSDIV (Logging ADCI, ADCQ and FSDIVNA); 2=IQANDAGC (Logging ADCI, ADCQ and AGC gain settings); 3=AGCANDDATA (Logging AGC gain settings and output data bits)
0xA44 ACQAHBCNF — Data acquisition EasyDMA AHB configuration register (refer to 4378_164)
  [0] ACQAHBCNF
    0=UTXRX (The EasyDMA channel in the TX/RX chain is using the AHB bus); 1=ACQ (The EasyDMA channel in the data acquisition module is using the AHB bus)
0xC00 PCGC_PENALTY — Power and clock
  [0] PCGC_PENALTY
0xC10 PCGC_OVERRIDE — Power and clock
  [0] PCGC_OVERRIDE
0xC20 PCGC_CLK_REQ — Power and clock
  [0] PCGC_CLK_REQ
0xD00 PCGC_BACKDOOR — Power and clock
  [0] PCGC_BACKDOOR
0xD04 PCGC_FORCEREG — Power and clock
  [0] PCGC_FORCEREG
0xFFC POWER reset 0x1 — Peripheral power control
  [0] POWER — Peripheral power control. The peripheral and its registers will be reset to its initial state by switching the peripheral off and then back on again.
    0=Disabled (Peripheral is powered off); 1=Enabled (Peripheral is powered on)
